# STM32MP13xx register map
File version: 1.7
CPU: CA7 r0p0, little endian, MPU, FPU, 4 interrupt priority bits
Registers are 32-bit, read-write, reset 0x0 unless marked. A register's access mark holds for its fields unless they carry their own. Offsets are from the block's base; [hi:lo] are bit positions; {n}, {i} and the like mark numbered series.

## MCE
Base 0x58001000
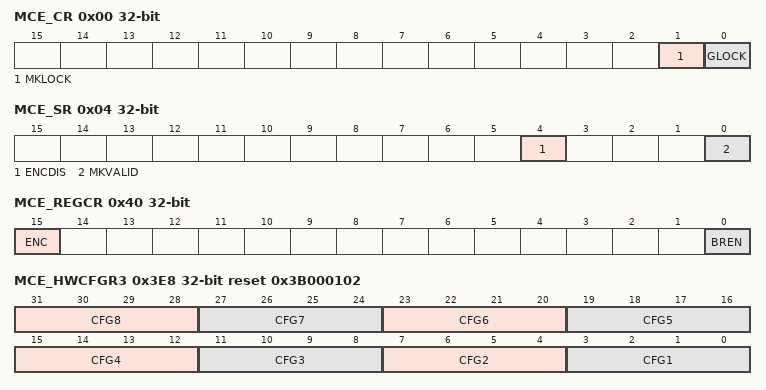
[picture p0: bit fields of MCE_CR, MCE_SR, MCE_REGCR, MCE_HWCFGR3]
0x00 MCE_CR — MCE configuration register
  [1] MKLOCK — Master keys lock Lock the master key configurations until next reset. This bit is cleared by default and once set it cannot be reset until MCE reset.
    0=Writes to MCE_MKEYRx register is allowed; 1=Writes to MCE_MKEYRx register is ignored until next MCE reset
  [0] GLOCK — Global lock Lock the configuration of most MCE registers until next reset. This bit is cleared by default and once set it cannot be reset until MCE reset.
    0=MCE registers are writable; 1=All writes to MCE registers are ignored, with the exception of MCE_IACR and MCE_IAIER registers
0x04 MCE_SR ro — MCE status register
  [4] ENCDIS — encryption disabled This bit is set by hardware when the encryption feature is not functional. When ENCDIS is set application must reset MCE peripheral to be able to use the encryption feature again.
    0=When ENC bit and BREN are set in MCE_REGCR all allowed write accesses are encrypted, and all allowed read requests are decrypted; 1=When ENC bit and BREN are set in MCE_REGCR all write accesses are ignored, and all read requests return zero. All previously written key material are also erased.
  [0] MKVALID — Master key valid
    0=A valid key has not been written in MCE_MKEYRx registers; 1=A valid key has been written in MCE_MKEYRx registers (write R0 -> R1 -> R2 -> R3 or the reverse)
0x08 MCE_IASR ro — MCE illegal access status register
  [0] CAEF — Configuration access error flag This bit is set when an illegal access to any MCE configuration register is detected. Bit is cleared by setting corresponding bit in MCE_IACR register. No additional details on the error is available.
0x0C MCE_IACR wo — MCE illegal access clear register
  [0] CAEF — Configuration access error flag clear Set this bit to clear CAEF bit in MCE_IASR register.
0x10 MCE_IAIER — MCE illegal access interrupt enable register
  [0] CAEIE — Configuration access error interrupt enable
    0=Interrupt generation on configuration access errors is disabled; 1=Interrupt generation when a configuration access error occurs (CAEF=1)
0x1C MCE_PRIVCFGR — MCE privileged configuration register
  [0] PRIV — Privileged configuration
    0=Privileged and unprivileged access are granted to MCE registers; 1=Only privileged access are granted to MCE registers, excluding ID registers (MCE_HWCFGR1/2, MCE_VERR, MCE_IPIDR, MCE_SIDR)
0x40 MCE_REGCR — MCE region x configuration register
  [15] ENC — Encrypted region This bit is taken into account only if BREN is set.
    0=No effects; 1=All allowed read (resp. write) requests are decrypted (resp. encrypted) using the block cipher. If MKVALID=0 bypass mode is selected instead.
  [0] BREN — Base region enable BREN cannot be set if BADDRSTART > BADDREND.
    0=Region is disabled. Access control of primary region (any-privilege, no encryption) applies to any access between this region start and end addresses.; 1=Region is enable. Access controls and encryption option defined in this region apply to any access between this region start and end addresses.
0x44 MCE_SADDR — MCE start address register
  [31:16] BADDSTART — Region address start This bitfield defines the absolute start address of the region on 64 kBytes boundary (inclusive). BREN cannot be set if BADDRSTART > BADDREND. When MCE determines the region, the first 16 bits (LSB) and the last 2 bits (MSB) in this register are ignored, and when this register is accessed in read the 2 MSB bits and the 16 LSB bits return zeros (reference value in MCE).
0x48 MCE_EADDR reset 0xFFFF — MCE end address register
  [31:16] BADDEND — Region address end This bitfield defines the absolute end address of the region on 64 kBytes boundary (inclusive). BREN cannot be set if BADDRSTART > BADDREND. When MCE determines the region, the first 16 bits (LSB) and the last 2 bits (MSB) in this register are ignored, and when this register is accessed in read the 2 MSB bits return zeros and the 16 LSB bits return ones (reference value in MCE).
{0x200+4i} MCE_MKEYR{i} wo (i=0..3) — MCE master key {i}
  [31:0] MKEY — Master key, bits [{32i+31}:{32i}] This key is used by the MCE block cipher
0x3E8 MCE_HWCFGR3 ro reset 0x3B000102 — MCE version register
  [31:28] CFG8 — HW Generic 8 This field returns the generic value ooo_enable | interconnect_enable
  [27:24] CFG7 — HW Generic 7 This field returns the generic value id_size
  [23:20] CFG6 — HW Generic 6 This field returns the generic value priv_enable_axi
  [19:16] CFG5 — HW Generic 5 This field returns the generic value rif_enable
  [15:12] CFG4 — HW Generic 4 This field returns the generic value sec_enable
  [11:8] CFG3 — HW Generic 3 This field returns the generic value priv_enable
  [7:4] CFG2 — HW Generic 2 This field returns the generic value nk_core
  [3:0] CFG1 — HW Generic 1 This field returns the generic value aes_core
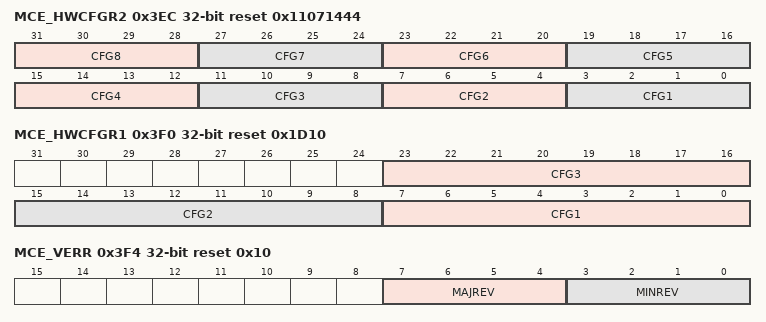
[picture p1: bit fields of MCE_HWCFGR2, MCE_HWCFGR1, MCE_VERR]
0x3EC MCE_HWCFGR2 ro reset 0x11071444 — MCE version register
  [31:28] CFG8 — HW Generic 8 This field returns the generic value nb_breg
  [27:24] CFG7 — HW Generic 7 This field returns the generic value nb_mkey
  [23:20] CFG6 — HW Generic 6 This field returns the generic value nb_cctx
  [19:16] CFG5 — HW Generic 5 This field returns the generic value nb_dpa_cycles
  [15:12] CFG4 — HW Generic 4 This field returns the generic value ilac_is_int
  [11:8] CFG3 — HW Generic 3 This field returns the generic value mask_fifo_depth
  [7:4] CFG2 — HW Generic 2 This field returns the generic value info_fifo_depth
  [3:0] CFG1 — HW Generic 1 This field returns the generic value burst_fifo_depth
0x3F0 MCE_HWCFGR1 ro reset 0x1D10 — MCE version register
  [23:16] CFG3 — HW Generic 3 This field returns the generic value opbits_gen
  [15:8] CFG2 — HW Generic 2 This field returns the generic value address_region_msb_max_bits
  [7:0] CFG1 — HW Generic 1 This field returns the generic value address_region_lsb_max_bits
0x3F4 MCE_VERR ro reset 0x10 — MCE version register
  [7:4] MAJREV — Major revision This field returns the MCE IP Major Version.
  [3:0] MINREV — Minor revision This field returns the MCE IP Minor Version.
0x3F8 MCE_IPIDR ro reset 0x170081 — MCE identification register
  [31:0] ID — Identification Code This field returns the identification code of the MCE IP.
0x3FC MCE_SIDR ro reset 0xA3C5DD01 — MCE size ID register
  [31:0] SID — Size Identification Code This field returns the size identification code of the MCE IP as defined below: Bits[31:8] = 0xA3C5DD (fixed code) Bits[7:0] = 0x01 (1KB address decoding)
